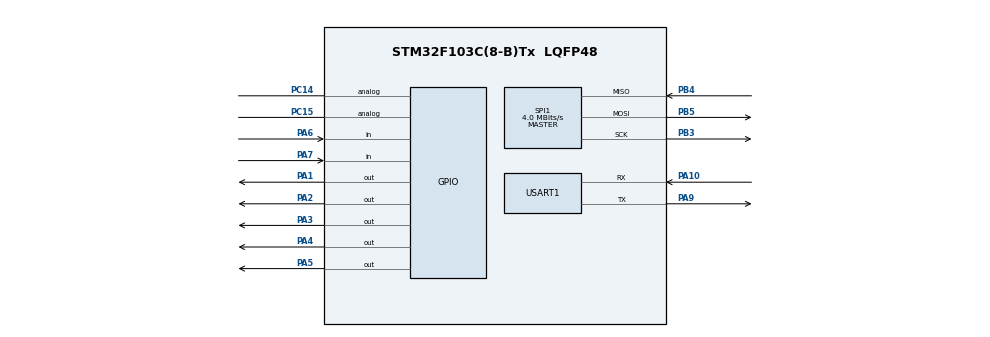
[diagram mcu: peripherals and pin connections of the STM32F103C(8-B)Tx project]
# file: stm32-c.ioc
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Mcu.Family=STM32F1
Mcu.Name=STM32F103C(8-B)Tx
Mcu.Package=LQFP48
NVIC.PriorityGroup=NVIC_PRIORITYGROUP_4
PA1.Signal=GPIO_Output
PA10.Mode=Asynchronous
PA10.Signal=USART1_RX
PA2.Signal=GPIO_Output
PA3.Signal=GPIO_Output
PA4.Signal=GPIO_Output
PA5.Signal=GPIO_Output
PA6.Signal=GPIO_Input
PA7.Signal=GPIO_Input
PA9.Mode=Asynchronous
PA9.Signal=USART1_TX
PB3.Mode=Full_Duplex_Master
PB3.Signal=SPI1_SCK
PB4.Mode=Full_Duplex_Master
PB4.Signal=SPI1_MISO
PB5.Mode=Full_Duplex_Master
PB5.Signal=SPI1_MOSI
PC14-OSC32_IN.Signal=GPIO_Analog
PC15-OSC32_OUT.Signal=GPIO_Analog
ProjectManager.HeapSize=0x200
ProjectManager.StackSize=0x400
ProjectManager.TargetToolchain=STM32CubeIDE
RCC.APB1Freq_Value=8000000
RCC.APB2Freq_Value=8000000
SPI1.CalculateBaudRate=4.0 MBits/s
SPI1.Direction=SPI_DIRECTION_2LINES
SPI1.Mode=SPI_MODE_MASTER
SPI1.VirtualType=VM_MASTER
USART1.VirtualMode=VM_ASYNC
VP_SYS_VS_ND.Mode=No_Debug
board=custom

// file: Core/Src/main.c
/* USER CODE BEGIN Header */
/**
  ******************************************************************************
  * @file           : main.c
  * @brief          : Main program body
  ******************************************************************************
  * @attention
  *
  * Copyright (c) 2024 STMicroelectronics.
  * All rights reserved.
  *
  * This software is licensed under terms that can be found in the LICENSE file
  * in the root directory of this software component.
  * If no LICENSE file comes with this software, it is provided AS-IS.
  *
  ******************************************************************************
  */
/* USER CODE END Header */
#include "main.h"
#include "stm32f1xx_hal.h"
#include <string.h>
#include <stdio.h>

SPI_HandleTypeDef hspi1;

UART_HandleTypeDef huart1;

void SystemClock_Config(void);
static void MX_GPIO_Init(void);
static void MX_SPI1_Init(void);
static void MX_USART1_UART_Init(void);
UART_HandleTypeDef huart1;
char buffer[16];

void read_and_display_distance() {
    HAL_GPIO_WritePin(GPIOA, GPIO_PIN_1, GPIO_PIN_RESET);
    HAL_Delay(1000);
    HAL_GPIO_WritePin(GPIOA, GPIO_PIN_1, GPIO_PIN_SET);
    HAL_Delay(1000);
    HAL_GPIO_WritePin(GPIOA, GPIO_PIN_1, GPIO_PIN_RESET);

    uint32_t dist = HAL_GPIO_ReadPin(GPIOA, GPIO_PIN_6);  // Read sensor pin
    dist = dist / 58;  // Calculate distance from sensor reading

    sprintf(buffer, "Dist: %lu cm\r\n", dist);  // Convert distance to string

    HAL_UART_Transmit(&huart1, (uint8_t *)buffer, strlen(buffer), HAL_MAX_DELAY);  // Send distance over UART
}

int main(void)
{

  /* USER CODE BEGIN 1 */
    HAL_Init();
    SystemClock_Config();

    // Initialize GPIO for sensor
    __HAL_RCC_GPIOA_CLK_ENABLE();
    GPIO_InitTypeDef GPIO_InitStruct = {0};

    GPIO_InitStruct.Pin = GPIO_PIN_1 | GPIO_PIN_6;
    GPIO_InitStruct.Mode = GPIO_MODE_OUTPUT_PP;
    GPIO_InitStruct.Speed = GPIO_SPEED_FREQ_LOW;
    HAL_GPIO_Init(GPIOA, &GPIO_InitStruct);

    HAL_UART_Init(&huart1);
 // Initialize UART
  /* USER CODE END 1 */

  /* MCU Configuration--------------------------------------------------------*/

  /* Reset of all peripherals, Initializes the Flash interface and the Systick. */
  HAL_Init();

  /* Configure the system clock */

  /* Initialize all configured peripherals */
  MX_GPIO_Init();
  MX_SPI1_Init();
  MX_USART1_UART_Init();

  /* Infinite loop */
  while (1)
  {
      read_and_display_distance();  // Read and display distance
      HAL_Delay(1000);  // Delay between readings
  }
}

void SystemClock_Config(void)
{
  RCC_OscInitTypeDef RCC_OscInitStruct = {0};
  RCC_ClkInitTypeDef RCC_ClkInitStruct = {0};

  /** Initializes the RCC Oscillators according to the specified parameters
  * in the RCC_OscInitTypeDef structure.
  */
  RCC_OscInitStruct.OscillatorType = RCC_OSCILLATORTYPE_HSI;
  RCC_OscInitStruct.HSIState = RCC_HSI_ON;
  RCC_OscInitStruct.HSICalibrationValue = RCC_HSICALIBRATION_DEFAULT;
  RCC_OscInitStruct.PLL.PLLState = RCC_PLL_NONE;
  if (HAL_RCC_OscConfig(&RCC_OscInitStruct) != HAL_OK)
  {
    Error_Handler();
  }

  /** Initializes the CPU, AHB and APB buses clocks
  */
  RCC_ClkInitStruct.ClockType = RCC_CLOCKTYPE_HCLK|RCC_CLOCKTYPE_SYSCLK
                              |RCC_CLOCKTYPE_PCLK1|RCC_CLOCKTYPE_PCLK2;
  RCC_ClkInitStruct.SYSCLKSource = RCC_SYSCLKSOURCE_HSI;
  RCC_ClkInitStruct.AHBCLKDivider = RCC_SYSCLK_DIV1;
  RCC_ClkInitStruct.APB1CLKDivider = RCC_HCLK_DIV1;
  RCC_ClkInitStruct.APB2CLKDivider = RCC_HCLK_DIV1;

  if (HAL_RCC_ClockConfig(&RCC_ClkInitStruct, FLASH_LATENCY_0) != HAL_OK)
  {
    Error_Handler();
  }
}

static void MX_SPI1_Init(void)
{

  /* SPI1 parameter configuration*/
  hspi1.Instance = SPI1;
  hspi1.Init.Mode = SPI_MODE_MASTER;
  hspi1.Init.Direction = SPI_DIRECTION_2LINES;
  hspi1.Init.DataSize = SPI_DATASIZE_8BIT;
  hspi1.Init.CLKPolarity = SPI_POLARITY_LOW;
  hspi1.Init.CLKPhase = SPI_PHASE_1EDGE;
  hspi1.Init.NSS = SPI_NSS_SOFT;
  hspi1.Init.BaudRatePrescaler = SPI_BAUDRATEPRESCALER_2;
  hspi1.Init.FirstBit = SPI_FIRSTBIT_MSB;
  hspi1.Init.TIMode = SPI_TIMODE_DISABLE;
  hspi1.Init.CRCCalculation = SPI_CRCCALCULATION_DISABLE;
  hspi1.Init.CRCPolynomial = 10;
  if (HAL_SPI_Init(&hspi1) != HAL_OK)
  {
    Error_Handler();
  }

}

static void MX_USART1_UART_Init(void)
{

  huart1.Instance = USART1;
  huart1.Init.BaudRate = 115200;
  huart1.Init.WordLength = UART_WORDLENGTH_8B;
  huart1.Init.StopBits = UART_STOPBITS_1;
  huart1.Init.Parity = UART_PARITY_NONE;
  huart1.Init.Mode = UART_MODE_TX_RX;
  huart1.Init.HwFlowCtl = UART_HWCONTROL_NONE;
  huart1.Init.OverSampling = UART_OVERSAMPLING_16;
  if (HAL_HalfDuplex_Init(&huart1) != HAL_OK)
  {
    Error_Handler();
  }

}

static void MX_GPIO_Init(void)
{
  GPIO_InitTypeDef GPIO_InitStruct = {0};

  /* GPIO Ports Clock Enable */
  __HAL_RCC_GPIOC_CLK_ENABLE();
  __HAL_RCC_GPIOA_CLK_ENABLE();
  __HAL_RCC_GPIOB_CLK_ENABLE();

  /*Configure GPIO pin Output Level */
  HAL_GPIO_WritePin(GPIOA, GPIO_PIN_1|GPIO_PIN_2|GPIO_PIN_3|GPIO_PIN_4
                          |GPIO_PIN_5, GPIO_PIN_RESET);

  /*Configure GPIO pins : PC14 PC15 */
  GPIO_InitStruct.Pin = GPIO_PIN_14|GPIO_PIN_15;
  GPIO_InitStruct.Mode = GPIO_MODE_ANALOG;
  HAL_GPIO_Init(GPIOC, &GPIO_InitStruct);

  /*Configure GPIO pins : PA1 PA2 PA3 PA4
                           PA5 */
  GPIO_InitStruct.Pin = GPIO_PIN_1|GPIO_PIN_2|GPIO_PIN_3|GPIO_PIN_4
                          |GPIO_PIN_5;
  GPIO_InitStruct.Mode = GPIO_MODE_OUTPUT_PP;
  GPIO_InitStruct.Pull = GPIO_NOPULL;
  GPIO_InitStruct.Speed = GPIO_SPEED_FREQ_LOW;
  HAL_GPIO_Init(GPIOA, &GPIO_InitStruct);

  /*Configure GPIO pins : PA6 PA7 */
  GPIO_InitStruct.Pin = GPIO_PIN_6|GPIO_PIN_7;
  GPIO_InitStruct.Mode = GPIO_MODE_INPUT;
  GPIO_InitStruct.Pull = GPIO_NOPULL;
  HAL_GPIO_Init(GPIOA, &GPIO_InitStruct);

}

void Error_Handler(void)
{
  __disable_irq();
  while (1)
  {
  }
}
